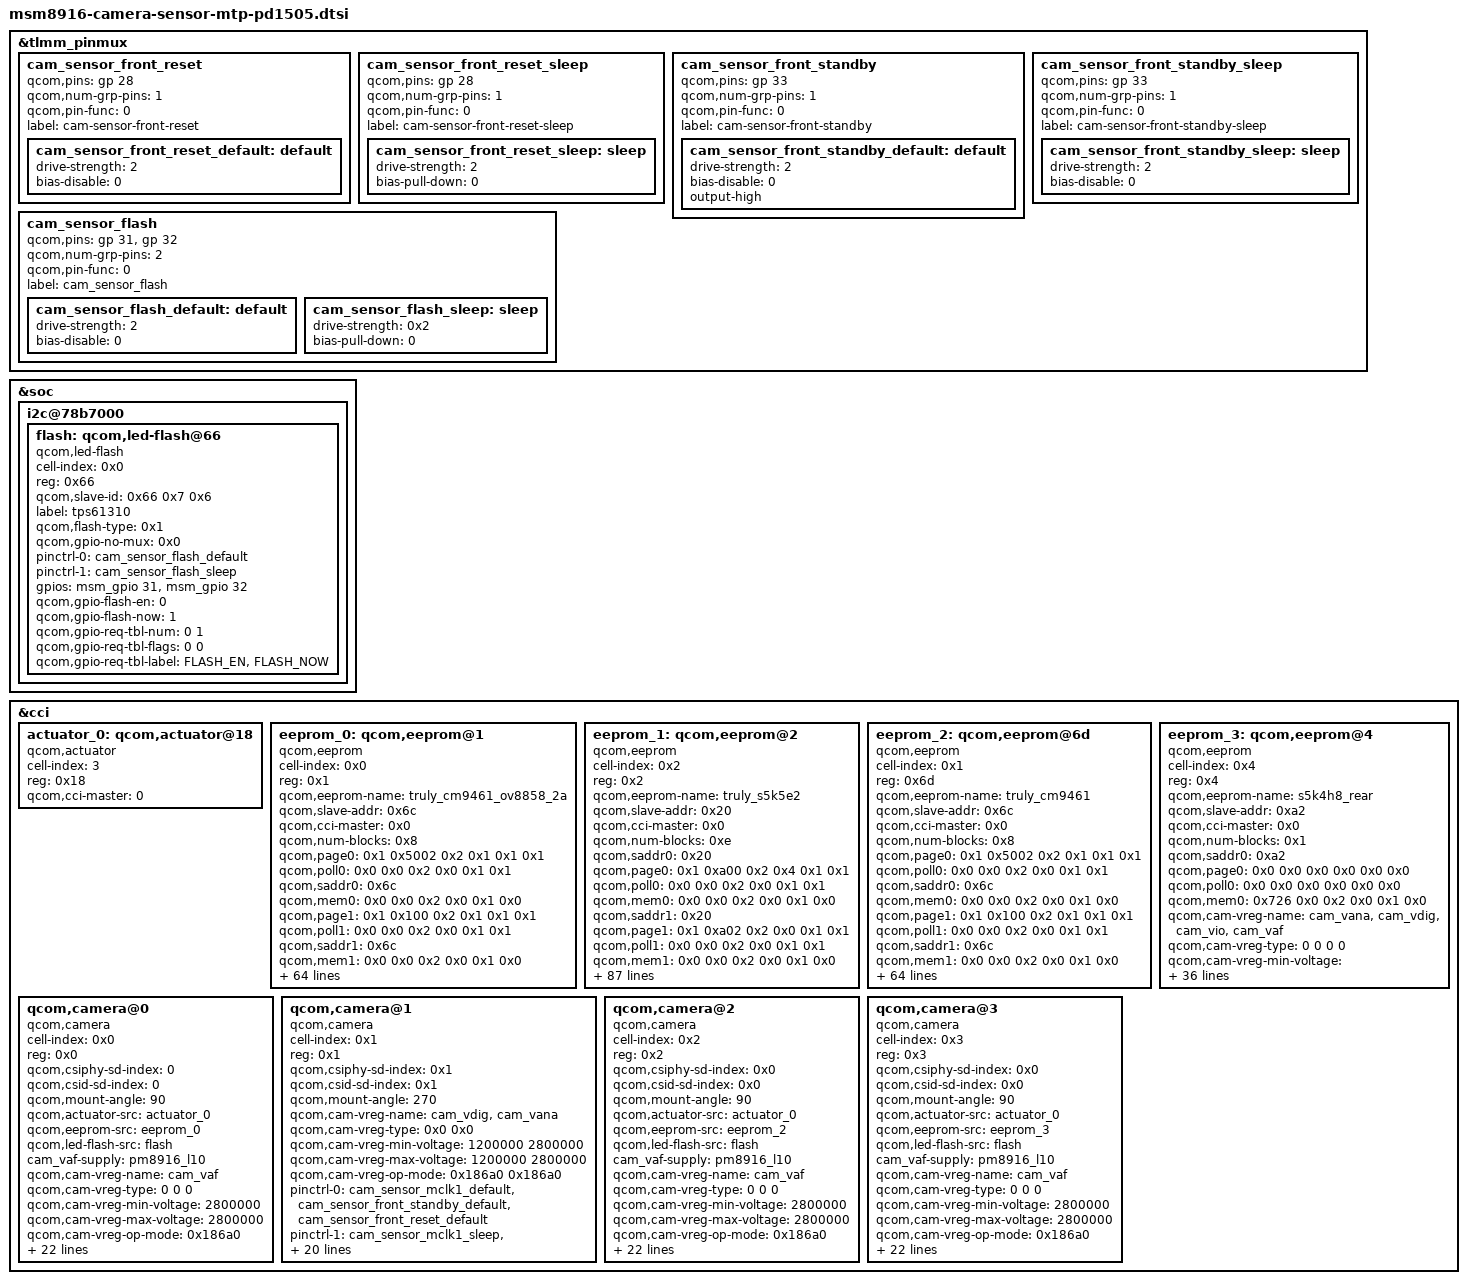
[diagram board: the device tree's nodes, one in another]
/* Copyright (c) 2020, The Linux Foundation. All rights reserved.
*  Copyright (c) 2020, the_shahnawaz_sheikh (sheikhshahnawaz41299).
*
* This program is free software; you can redistribute it and/or modify
* it under the terms of the GNU General Public License version 2 and
* only version 2 as published by the Free Software Foundation.
*
* This program is distributed in the hope that it will be useful,
* but WITHOUT ANY WARRANTY; without even the implied warranty of
* MERCHANTABILITY or FITNESS FOR A PARTICULAR PURPOSE.  See the
* GNU General Public License for more details.
*/

&tlmm_pinmux {
    
	cam_sensor_front_reset {
				qcom,pins = <&gp 28>;
				qcom,num-grp-pins = <1>;
				qcom,pin-func = <0>;
				label = "cam-sensor-front-reset";

			cam_sensor_front_reset_default:	default {
					drive-strength = <2>;
					bias-disable = <0>;
				};
			};
			
	cam_sensor_front_reset_sleep {
				qcom,pins = <&gp 28>;
				qcom,num-grp-pins = <1>;
				qcom,pin-func = <0>;
				label = "cam-sensor-front-reset-sleep";

			cam_sensor_front_reset_sleep: sleep {
					drive-strength = <2>;
					bias-pull-down = <0>;
				};
	};

	cam_sensor_front_standby {
				qcom,pins = <&gp 33>;
				qcom,num-grp-pins = <1>;
				qcom,pin-func = <0>;
				label = "cam-sensor-front-standby";

				cam_sensor_front_standby_default: default {
					drive-strength = <2>;
					bias-disable = <0>;
					output-high;
				};
	};

	cam_sensor_front_standby_sleep {
				qcom,pins = <&gp 33>;
				qcom,num-grp-pins = <1>;
				qcom,pin-func = <0>;
				label = "cam-sensor-front-standby-sleep";

			cam_sensor_front_standby_sleep:	sleep {
					drive-strength = <2>;
					bias-disable = <0>;
				};
	};
	
	cam_sensor_flash {
				qcom,pins = <&gp 31 &gp 32>;
				qcom,num-grp-pins = <2>;
				qcom,pin-func = <0>;
				label = "cam_sensor_flash";

			cam_sensor_flash_default:	default {
					drive-strength = <2>;
					bias-disable = <0>;
				};

				cam_sensor_flash_sleep: sleep {
					drive-strength = <0x2>;
					bias-pull-down = <0>;
				};
	};
};

&soc {
    
	i2c@78b7000 {
	   flash: qcom,led-flash@66 {
				cell-index = <0x0>;
				reg = <0x66>;
				qcom,slave-id = <0x66 0x7 0x6>;
				compatible = "qcom,led-flash";
				label = "tps61310";
				qcom,flash-type = <0x1>;
				qcom,gpio-no-mux = <0x0>;
				pinctrl-names = "cam_flash_default", "cam_flash_suspend";
				pinctrl-0 = <&cam_sensor_flash_default>;
				pinctrl-1 = <&cam_sensor_flash_sleep>;
				gpios = <&msm_gpio 31 0>,
				        <&msm_gpio 32 0>;
				qcom,gpio-flash-en = <0>;
				qcom,gpio-flash-now = <1>;
				qcom,gpio-req-tbl-num = <0 1>;
				qcom,gpio-req-tbl-flags = <0 0>;
				qcom,gpio-req-tbl-label = "FLASH_EN", "FLASH_NOW";
			};
	};
};

&cci {
	/delete-node/ qcom,actuator@0;
	/delete-node/ qcom,led-flash@0;

	actuator_0: qcom,actuator@18 {
		cell-index = <3>;
		reg = <0x18>;
		compatible = "qcom,actuator";
		qcom,cci-master = <0>;
	};

	/delete-node/ qcom,eeprom@20;
	/delete-node/ qcom,eeprom@1;

	eeprom_0: qcom,eeprom@1 {
				cell-index = <0x0>;
				reg = <0x1>;
				qcom,eeprom-name = "truly_cm9461_ov8858_2a";
				compatible = "qcom,eeprom";
				qcom,slave-addr = <0x6c>;
				qcom,cci-master = <0x0>;
				qcom,num-blocks = <0x8>;
				
				qcom,page0 = <0x1 0x5002 0x2 0x1 0x1 0x1>;
				qcom,poll0 = <0x0 0x0 0x2 0x0 0x1 0x1>;
				qcom,saddr0 = <0x6c>;
				qcom,mem0 = <0x0 0x0 0x2 0x0 0x1 0x0>;
				
				qcom,page1 = <0x1 0x100 0x2 0x1 0x1 0x1>;
				qcom,poll1 = <0x0 0x0 0x2 0x0 0x1 0x1>;
				qcom,saddr1 = <0x6c>;
				qcom,mem1 = <0x0 0x0 0x2 0x0 0x1 0x0>;
				
				qcom,page2 = <0x1 0x3d88 0x2 0x70 0x1 0x1>;
				qcom,poll2 = <0x0 0x0 0x2 0x0 0x1 0x1>;
				qcom,saddr2 = <0x6c>;
				qcom,mem2 = <0x0 0x0 0x2 0x0 0x1 0x0>;
				
				qcom,page3 = <0x1 0x3d89 0x2 0x10 0x1 0x1>;
				qcom,poll3 = <0x0 0x0 0x2 0x0 0x1 0x1>;
				qcom,saddr3 = <0x6c>;
				qcom,mem3 = <0x0 0x0 0x2 0x0 0x1 0x0>;
				
				qcom,page4 = <0x1 0x3d8a 0x2 0x72 0x1 0x1>;
				qcom,poll4 = <0x0 0x0 0x2 0x0 0x1 0x1>;
				qcom,saddr4 = <0x6c>;
				qcom,mem4 = <0x0 0x0 0x2 0x0 0x1 0x0>;
				
				qcom,page5 = <0x1 0x3d8b 0x2 0xa 0x1 0x1>;
				qcom,poll5 = <0x0 0x0 0x2 0x0 0x1 0x1>;
				qcom,saddr5 = <0x6c>;
				qcom,mem5 = <0x0 0x0 0x2 0x0 0x1 0x0>;
				
				qcom,page6 = <0x1 0x3d84 0x2 0xc0 0x1 0x1>;
				qcom,pageen6 = <0x1 0x3d81 0x2 0x1 0x1 0xa>;
				qcom,poll6 = <0x0 0x0 0x2 0x0 0x1 0x1>;
				qcom,saddr6 = <0x6c>;
				qcom,mem6 = <0x1fb 0x7010 0x2 0x0 0x1 0x0>;
				
				qcom,page7 = <0x1 0x5002 0x2 0x8 0x1 0x1>;
				qcom,poll7 = <0x0 0x0 0x2 0x0 0x1 0x1>;
				qcom,saddr7 = <0x6c>;
				qcom,mem7 = <0x0 0x0 0x2 0x0 0x1 0x0>;
				
				qcom,cam-vreg-name = "cam_vana", "cam_vdig", "cam_vio", "cam_vaf";
				qcom,cam-vreg-type = <0 0 0 0>;
				qcom,cam-vreg-min-voltage = <2850000 1200000 1800000 280000>;
				qcom,cam-vreg-max-voltage = <2850000 1200000 1800000 280000>;
				qcom,cam-vreg-op-mode = <0x186a0 0x186a0 0x186a0 0x186a0>;
				
				pinctrl-names = "cam_default", "cam_suspend";
				pinctrl-0 = <&cam_sensor_mclk0_default &cam_sensor_rear_default>;
				pinctrl-1 = <&cam_sensor_mclk0_sleep &cam_sensor_rear_sleep>;
				gpios = <&msm_gpio 26 0>,
				        <&msm_gpio 35 0>,
						<&msm_gpio 52 0>,
						<&msm_gpio 1 0>,
						<&msm_gpio 16 0>,
						<&msm_gpio 34 0>;
				qcom,gpio-reset = <1>;
				qcom,gpio-vana = <2>;
				qcom,gpio-vdig = <3>;
				qcom,gpio-vio = <4>;
				qcom,gpio-standby = <5>;
				qcom,gpio-req-tbl-num = <0 1 2 3 4 5>;
				qcom,gpio-req-tbl-flags = <1 0 0 0 0 0>;
				qcom,csi-lane-assign = <0x4320>;
				qcom,csi-lane-mask = <0x1f>;
				qcom,gpio-req-tbl-label = "CAMIF_MCLK",
				                     "CAM_RESET1",
									 "CAM_VANA",
									 "CAM_VDIG",
									 "CAM_VIO",
									 "CAM_STANDBY";
				qcom,cam-power-seq-type = "sensor_gpio", "sensor_gpio", "sensor_gpio",
				                       "sensor_clk", "sensor_gpio", "sensor_gpio";
				qcom,cam-power-seq-val = "sensor_gpio_vio", "sensor_gpio_vana", "sensor_gpio_vdig", 
				                    "sensor_cam_mclk", "sensor_gpio_standby", "sensor_gpio_reset";
				qcom,cam-power-seq-cfg-val = <1 1 1 23880000 1 1>;
				qcom,cam-power-seq-delay = <1 1 1 5 5 10>;
				qcom,mclk-23880000;
				clocks = <&clock_gcc clk_mclk0_clk_src>,
			            <&clock_gcc clk_gcc_camss_mclk0_clk>;
		        clock-names = "cam_src_clk", "cam_clk";
			};

	eeprom_1: qcom,eeprom@2 {
				cell-index = <0x2>;
				reg = <0x2>;
				qcom,eeprom-name = "truly_s5k5e2";
				compatible = "qcom,eeprom";
				qcom,slave-addr = <0x20>;
				qcom,cci-master = <0x0>;
				qcom,num-blocks = <0xe>;
				
				qcom,saddr0 = <0x20>;
				qcom,page0 = <0x1 0xa00 0x2 0x4 0x1 0x1>;
				qcom,poll0 = <0x0 0x0 0x2 0x0 0x1 0x1>;
				qcom,mem0 = <0x0 0x0 0x2 0x0 0x1 0x0>;
				
				qcom,saddr1 = <0x20>;
				qcom,page1 = <0x1 0xa02 0x2 0x0 0x1 0x1>;
				qcom,poll1 = <0x0 0x0 0x2 0x0 0x1 0x1>;
				qcom,mem1 = <0x0 0x0 0x2 0x0 0x1 0x0>;
				
				qcom,saddr2 = <0x20>;
				qcom,page2 = <0x1 0xa00 0x2 0x1 0x1 0x1>;
				qcom,poll2 = <0x0 0x0 0x2 0x0 0x1 0x1>;
				qcom,mem2 = <0x0 0x0 0x2 0x0 0x1 0x0>;
				
				qcom,saddr3 = <0x20>;
				qcom,page3 = <0x1 0xa02 0x2 0x2 0x1 0x1>;
				qcom,pageen3 = <0x0 0x0 0x2 0x0 0x1 0x1>;
				qcom,poll3 = <0x0 0x0 0x2 0x0 0x1 0x1>;
				qcom,mem3 = <0x40 0xa04 0x2 0x0 0x1 0x0>;
				
				qcom,saddr4 = <0x20>;
				qcom,page4 = <0x1 0xa00 0x2 0x4 0x1 0x1>;
				qcom,poll4 = <0x0 0x0 0x2 0x0 0x1 0x1>;
				qcom,mem4 = <0x0 0x0 0x2 0x0 0x1 0x0>;
				
				qcom,saddr5 = <0x20>;
				qcom,page5 = <0x1 0xa02 0x2 0x1 0x1 0x1>;
				qcom,poll5 = <0x0 0x0 0x2 0x0 0x1 0x1>;
				qcom,mem5 = <0x0 0x0 0x2 0x0 0x1 0x0>;
				
				qcom,saddr6 = <0x20>;
				qcom,page6 = <0x1 0xa00 0x2 0x1 0x1 0x1>;
				qcom,poll6 = <0x0 0x0 0x2 0x0 0x1 0x1>;
				qcom,mem6 = <0x0 0x0 0x2 0x0 0x1 0x0>;
				
				qcom,saddr7 = <0x20>;
				qcom,page7 = <0x1 0xa02 0x2 0x3 0x1 0x1>;
				qcom,pageen7 = <0x0 0x0 0x2 0x0 0x1 0x1>;
				qcom,poll7 = <0x0 0x0 0x2 0x0 0x1 0x1>;
				qcom,mem7 = <0x40 0xa04 0x2 0x0 0x1 0x0>;
				
				qcom,saddr8 = <0x20>;
				qcom,page8 = <0x1 0xa00 0x2 0x4 0x1 0x1>;
				qcom,poll8 = <0x0 0x0 0x2 0x0 0x1 0x1>;
				qcom,mem8 = <0x0 0x0 0x2 0x0 0x1 0x0>;
				
				qcom,saddr9 = <0x20>;
				qcom,page9 = <0x1 0xa02 0x2 0x2 0x1 0x1>;
				qcom,poll9 = <0x0 0x0 0x2 0x0 0x1 0x1>;
				qcom,mem9 = <0x0 0x0 0x2 0x0 0x1 0x0>;
				
				qcom,saddr10 = <0x20>;
				qcom,page10 = <0x1 0xa00 0x2 0x1 0x1 0x1>;
				qcom,poll10 = <0x0 0x0 0x2 0x0 0x1 0x1>;
				qcom,mem10 = <0x0 0x0 0x2 0x0 0x1 0x0>;
				
				qcom,saddr11 = <0x20>;
				qcom,page11 = <0x1 0xa02 0x2 0x4 0x1 0x1>;
				qcom,pageen11 = <0x0 0x0 0x2 0x0 0x1 0x1>;
				qcom,poll11 = <0x0 0x0 0x2 0x0 0x1 0x1>;
				qcom,mem11 = <0x40 0xa04 0x2 0x0 0x1 0x0>;
				
				qcom,saddr12 = <0x20>;
				qcom,page12 = <0x1 0xa00 0x2 0x4 0x1 0x1>;
				qcom,poll12 = <0x0 0x0 0x2 0x0 0x1 0x1>;
				qcom,mem12 = <0x0 0x0 0x2 0x0 0x1 0x0>;
				
				qcom,saddr13 = <0x20>;
				qcom,page13 = <0x1 0xa00 0x2 0x0 0x1 0x1>;
				qcom,poll13 = <0x0 0x0 0x2 0x0 0x1 0x1>;
				qcom,mem13 = <0x0 0x0 0x2 0x0 0x1 0x0>;
				
				qcom,cam-vreg-name = "cam_vdig", "cam_vana";
				qcom,cam-vreg-type = <0 0>;
				qcom,cam-vreg-min-voltage = <1200000 2800000>;
				qcom,cam-vreg-max-voltage = <1200000 2800000>;
				qcom,cam-vreg-op-mode = <0x186a0 0x186a0>;
				qcom,gpio-no-mux = <0>;
				pinctrl-names = "cam_default", "cam_suspend";
				pinctrl-0 = <&cam_sensor_mclk1_default &cam_sensor_front_default>;
				pinctrl-1 = <&cam_sensor_mclk1_sleep &cam_sensor_front_sleep>;
				gpios = <&msm_gpio 27 0>,
				        <&msm_gpio 28 0>,
						<&msm_gpio 33 0>,
						<&msm_gpio 52 0>,
						<&msm_gpio 1 0>,
						<&msm_gpio 16 0>;
				qcom,gpio-reset = <1>;
				qcom,gpio-standby = <2>;
				qcom,gpio-vana = <3>;
				qcom,gpio-vdig = <4>;
				qcom,gpio-vio = <5>;
				qcom,gpio-req-tbl-num = <0 1 2 3 4 5>;
				qcom,gpio-req-tbl-flags = <1 0 0 0 0 0>;
				qcom,csi-lane-assign = <0x4320>;
				qcom,csi-lane-mask = <0x7>;
				qcom,gpio-req-tbl-label = "CAMIF_MCLK", "CAM_RESET", "CAM_STANDBY",
				                       "CAM_VANA1", "CAM_VDIG1", "CAM_VIO";
				qcom,cam-power-seq-type = "sensor_gpio", "sensor_gpio", "sensor_gpio",
				                        "sensor_clk", "sensor_gpio", "sensor_gpio";
				qcom,cam-power-seq-val = "sensor_gpio_vio", "sensor_gpio_vdig", "sensor_gpio_vana",
				                       "sensor_cam_mclk", "sensor_gpio_reset", "sensor_gpio_standby";
				qcom,cam-power-seq-cfg-val = <1 1 1 23880000 1 1>;
				qcom,cam-power-seq-delay = <5 5 5 5 10 10>;
				qcom,mclk-23880000;
				clocks = <&clock_gcc clk_mclk0_clk_src>,
			            <&clock_gcc clk_gcc_camss_mclk0_clk>;
		        clock-names = "cam_src_clk", "cam_clk";
			};

	eeprom_2: qcom,eeprom@6d {
				cell-index = <0x1>;
				reg = <0x6d>;
				qcom,eeprom-name = "truly_cm9461";
				compatible = "qcom,eeprom";
				qcom,slave-addr = <0x6c>;
				qcom,cci-master = <0x0>;
				qcom,num-blocks = <0x8>;
				qcom,page0 = <0x1 0x5002 0x2 0x1 0x1 0x1>;
				qcom,poll0 = <0x0 0x0 0x2 0x0 0x1 0x1>;
				
				qcom,saddr0 = <0x6c>;
				qcom,mem0 = <0x0 0x0 0x2 0x0 0x1 0x0>;
				
				qcom,page1 = <0x1 0x100 0x2 0x1 0x1 0x1>;
				qcom,poll1 = <0x0 0x0 0x2 0x0 0x1 0x1>;
				qcom,saddr1 = <0x6c>;
				qcom,mem1 = <0x0 0x0 0x2 0x0 0x1 0x0>;
				
				qcom,page2 = <0x1 0x3d88 0x2 0x70 0x1 0x1>;
				qcom,poll2 = <0x0 0x0 0x2 0x0 0x1 0x1>;
				qcom,saddr2 = <0x6c>;
				qcom,mem2 = <0x0 0x0 0x2 0x0 0x1 0x0>;
				
				qcom,page3 = <0x1 0x3d89 0x2 0x10 0x1 0x1>;
				qcom,poll3 = <0x0 0x0 0x2 0x0 0x1 0x1>;
				qcom,saddr3 = <0x6c>;
				qcom,mem3 = <0x0 0x0 0x2 0x0 0x1 0x0>;
				
				qcom,page4 = <0x1 0x3d8a 0x2 0x72 0x1 0x1>;
				qcom,poll4 = <0x0 0x0 0x2 0x0 0x1 0x1>;
				qcom,saddr4 = <0x6c>;
				qcom,mem4 = <0x0 0x0 0x2 0x0 0x1 0x0>;
				
				qcom,page5 = <0x1 0x3d8b 0x2 0xa 0x1 0x1>;
				qcom,poll5 = <0x0 0x0 0x2 0x0 0x1 0x1>;
				qcom,saddr5 = <0x6c>;
				qcom,mem5 = <0x0 0x0 0x2 0x0 0x1 0x0>;
				
				qcom,page6 = <0x1 0x3d84 0x2 0xc0 0x1 0x1>;
				qcom,pageen6 = <0x1 0x3d81 0x2 0x1 0x1 0xa>;
				qcom,poll6 = <0x0 0x0 0x2 0x0 0x1 0x1>;
				qcom,saddr6 = <0x6c>;
				qcom,mem6 = <0x1fb 0x7010 0x2 0x0 0x1 0x0>;
				
				qcom,page7 = <0x1 0x5002 0x2 0x8 0x1 0x1>;
				qcom,poll7 = <0x0 0x0 0x2 0x0 0x1 0x1>;
				qcom,saddr7 = <0x6c>;
				qcom,mem7 = <0x0 0x0 0x2 0x0 0x1 0x0>;
				
				qcom,cam-vreg-name = "cam_vana", "cam_vdig", "cam_vio", "cam_vaf";
				qcom,cam-vreg-type = <0x0 0x0 0x0 0x0>;
				qcom,cam-vreg-min-voltage = <2850000 1200000 1800000 280000>;
				qcom,cam-vreg-max-voltage = <2850000 1200000 1800000 280000>;
				qcom,cam-vreg-op-mode = <0x186a0 0x186a0 0x186a0 0x186a0>;
				pinctrl-names = "cam_default", "cam_suspend";
				pinctrl-0 = <&cam_sensor_mclk0_default &cam_sensor_rear_default>;
				pinctrl-1 = <&cam_sensor_mclk0_sleep &cam_sensor_rear_sleep>;
				gpios = <&msm_gpio 26 0>,
				         <&msm_gpio 35 0>,
						 <&msm_gpio 52 0>,
						 <&msm_gpio 1 0>,
						 <&msm_gpio 16 0>,
						 <&msm_gpio 34 0>;
				qcom,gpio-reset = <1>;
				qcom,gpio-vana = <2>;
				qcom,gpio-vdig = <3>;
				qcom,gpio-vio = <4>;
				qcom,gpio-standby = <5>;
				qcom,gpio-req-tbl-num = <0 1 2 3 4 5>;
				qcom,gpio-req-tbl-flags = <1 0 0 0 0 0>;
				qcom,csi-lane-assign = <0x4320>;
				qcom,csi-lane-mask = <0x1f>;
				qcom,gpio-req-tbl-label = "CAMIF_MCLK", "CAM_RESET1", "CAM_VANA", 
				                       "CAM_VDIG", "CAM_VIO", "CAM_STANDBY";
				qcom,cam-power-seq-type = "sensor_gpio", "sensor_gpio", "sensor_gpio",
				                         "sensor_clk", "sensor_gpio", "sensor_gpio";
				qcom,cam-power-seq-val = "sensor_gpio_vio", "sensor_gpio_vana", "sensor_gpio_vdig",
				                       "sensor_cam_mclk", "sensor_gpio_standby", "sensor_gpio_reset";
				qcom,cam-power-seq-cfg-val = <1 1 1 23880000 1 1>;
				qcom,cam-power-seq-delay = <1 1 1 5 5 10>;
				qcom,mclk-23880000;
				clocks = <&clock_gcc clk_mclk0_clk_src>,
			            <&clock_gcc clk_gcc_camss_mclk0_clk>;
		        clock-names = "cam_src_clk", "cam_clk";
			};

	eeprom_3: qcom,eeprom@4 {
				cell-index = <0x4>;
				reg = <0x4>;
				qcom,eeprom-name = "s5k4h8_rear";
				compatible = "qcom,eeprom";
				qcom,slave-addr = <0xa2>;
				qcom,cci-master = <0x0>;
				qcom,num-blocks = <0x1>;
				
				qcom,saddr0 = <0xa2>;
				qcom,page0 = <0x0 0x0 0x0 0x0 0x0 0x0>;
				qcom,poll0 = <0x0 0x0 0x0 0x0 0x0 0x0>;
				qcom,mem0 = <0x726 0x0 0x2 0x0 0x1 0x0>;
				
				qcom,cam-vreg-name = "cam_vana", "cam_vdig", "cam_vio", "cam_vaf";
				qcom,cam-vreg-type = <0 0 0 0>;
				qcom,cam-vreg-min-voltage = <2850000 1200000 1800000 280000>;
				qcom,cam-vreg-max-voltage = <2850000 1200000 1800000 280000>;
				qcom,cam-vreg-op-mode = <0x186a0 0x186a0 0x186a0 0x186a0>;
				
				pinctrl-names = "cam_default", "cam_suspend";
				pinctrl-0 = <&cam_sensor_mclk0_default &cam_sensor_rear_default>;
				pinctrl-1 = <&cam_sensor_mclk0_sleep &cam_sensor_rear_sleep>;
				gpios = <&msm_gpio 26 0>,
				        <&msm_gpio 35 0>,
						<&msm_gpio 52 0>,
						<&msm_gpio 1 0>,
						<&msm_gpio 16 0>,
						<&msm_gpio 34 0>;
				qcom,gpio-reset = <1>;
				qcom,gpio-vana = <2>;
				qcom,gpio-vdig = <3>;
				qcom,gpio-vio = <4>;
				qcom,gpio-standby = <5>;
				qcom,gpio-req-tbl-num = <0 1 2 3 4 5>;
				qcom,gpio-req-tbl-flags = <1 0 0 0 0 0>;
				qcom,csi-lane-assign = <0x4320>;
				qcom,csi-lane-mask = <0x1f>;
				qcom,gpio-req-tbl-label = "CAMIF_MCLK", "CAM_RESET1", "CAM_VANA",
				                         "CAM_VDIG", "CAM_VIO", "CAM_STANDBY";
				qcom,cam-power-seq-type = "sensor_gpio", "sensor_gpio", "sensor_gpio",
				                          "sensor_clk", "sensor_gpio", "sensor_gpio";
				qcom,cam-power-seq-val = "sensor_gpio_vio", "sensor_gpio_vana", "sensor_gpio_vdig", 
				                        "sensor_cam_mclk", "sensor_gpio_standby", "sensor_gpio_reset";
				qcom,cam-power-seq-cfg-val = <1 1 1 238800000 1 1>;
				qcom,cam-power-seq-delay = <1 1 1 5 5 10>;
				qcom,mclk-23880000;
				clocks = <&clock_gcc clk_mclk0_clk_src>,
			            <&clock_gcc clk_gcc_camss_mclk0_clk>;
		        clock-names = "cam_src_clk", "cam_clk";
			};

	/delete-node/ qcom,camera@78;
	/delete-node/ qcom,camera@0;
	/delete-node/ qcom,camera@1;

	qcom,camera@0 {
				cell-index = <0x0>;
				compatible = "qcom,camera";
				reg = <0x0>;
				qcom,csiphy-sd-index = <0>;
				qcom,csid-sd-index = <0>;
				qcom,mount-angle = <90>;
				qcom,actuator-src = <&actuator_0>;
				qcom,eeprom-src = <&eeprom_0>;
				qcom,led-flash-src = <&flash>;
				cam_vaf-supply = <&pm8916_l10>;
				qcom,cam-vreg-name = "cam_vaf";
				qcom,cam-vreg-type = <0 0 0>;
				qcom,cam-vreg-min-voltage = <2800000>;
				qcom,cam-vreg-max-voltage = <2800000>;
				qcom,cam-vreg-op-mode = <0x186a0>;
				pinctrl-names = "cam_default", "cam_suspend";
				pinctrl-0 = <&cam_sensor_mclk0_default &cam_sensor_rear_default>;
				pinctrl-1 = <&cam_sensor_mclk0_sleep &cam_sensor_rear_sleep>;
				gpios = <&msm_gpio 26 0>,
				        <&msm_gpio 35 0>,
						<&msm_gpio 34 0>,
						<&msm_gpio 52 0>,
						<&msm_gpio 1 0>,
						<&msm_gpio 16 0>;
				qcom,gpio-reset = <1>;
				qcom,gpio-standby = <2>;
				qcom,gpio-vana = <3>;
				qcom,gpio-vdig = <4>;
				qcom,gpio-vio = <5>;
				qcom,gpio-req-tbl-num = <0 1 2 3 4 5>;
				qcom,gpio-req-tbl-flags = <1 0 0 0 0 0>;
				qcom,gpio-req-tbl-label = "CAMIF_MCLK", "CAM_RESET1", "CAM_STANDBY", "CAM_VANA", "CAM_VDIG", "CAM_VIO";
				qcom,sensor-position = <0x0>;
				qcom,sensor-mode = <0x0>;
				qcom,cci-master = <0x0>;
				qcom,mclk-23880000;
				status = "ok";
				clocks = <&clock_gcc clk_mclk0_clk_src>,
			            <&clock_gcc clk_gcc_camss_mclk0_clk>;
		        clock-names = "cam_src_clk", "cam_clk";
			};

	qcom,camera@1 {
				cell-index = <0x1>;
				compatible = "qcom,camera";
				reg = <0x1>;
				qcom,csiphy-sd-index = <0x1>;
				qcom,csid-sd-index = <0x1>;
				qcom,mount-angle = <270>;
				qcom,cam-vreg-name = "cam_vdig", "cam_vana";
				qcom,cam-vreg-type = <0x0 0x0>;
				qcom,cam-vreg-min-voltage = <1200000 2800000>;
				qcom,cam-vreg-max-voltage = <1200000 2800000>;
				qcom,cam-vreg-op-mode = <0x186a0 0x186a0>;
				pinctrl-names = "cam_default", "cam_suspend";
				pinctrl-0 = <&cam_sensor_mclk1_default &cam_sensor_front_standby_default &cam_sensor_front_reset_default>;
				pinctrl-1 = <&cam_sensor_mclk1_sleep &cam_sensor_front_standby_sleep &cam_sensor_front_reset_sleep>;
				gpios = <&msm_gpio 27 0>,
				        <&msm_gpio 28 0>,
						<&msm_gpio 33 0>,
						<&msm_gpio 52 0>,
						<&msm_gpio 16 0>,
						<&msm_gpio 16 0>;
				qcom,gpio-reset = <1>;
				qcom,gpio-standby = <2>;
				qcom,gpio-vana = <3>;
				qcom,gpio-vdig = <4>;
				qcom,gpio-vio = <5>;
				qcom,gpio-req-tbl-num = <0 1 2 3 4 5>;
				qcom,gpio-req-tbl-flags = <1 0 0 0 0 0>;
				qcom,gpio-req-tbl-label = "CAMIF_MCLK", "CAM_RESET", "CAM_STANDBY", "CAM_VANA1", "CAM_VDIG1", "CAM_VIO";
				qcom,sensor-position = <1>;
				qcom,sensor-mode = <0x0>;
				qcom,cci-master = <0x0>;
				qcom,mclk-23880000;
				status = "ok";
				clocks = <&clock_gcc clk_mclk0_clk_src>,
			            <&clock_gcc clk_gcc_camss_mclk0_clk>;
		        clock-names = "cam_src_clk", "cam_clk";
			};

	qcom,camera@2 {
				cell-index = <0x2>;
				compatible = "qcom,camera";
				reg = <0x2>;
				qcom,csiphy-sd-index = <0x0>;
				qcom,csid-sd-index = <0x0>;
				qcom,mount-angle = <90>;
				qcom,actuator-src = <&actuator_0>;
				qcom,eeprom-src = <&eeprom_2>;
				qcom,led-flash-src = <&flash>;
				cam_vaf-supply = <&pm8916_l10>;
				qcom,cam-vreg-name = "cam_vaf";
				qcom,cam-vreg-type = <0 0 0>;
				qcom,cam-vreg-min-voltage = <2800000>;
				qcom,cam-vreg-max-voltage = <2800000>;
				qcom,cam-vreg-op-mode = <0x186a0>;
				pinctrl-names = "cam_default", "cam_suspend";
				pinctrl-0 = <&cam_sensor_mclk0_default &cam_sensor_rear_default>;
				pinctrl-1 = <&cam_sensor_mclk0_sleep &cam_sensor_rear_sleep>;
				gpios = <&msm_gpio 26 0>,
				        <&msm_gpio 35 0>,
						<&msm_gpio 34 0>,
						<&msm_gpio 52 0>,
						<&msm_gpio 1 0>,
						<&msm_gpio 16 0>;
				qcom,gpio-reset = <1>;
				qcom,gpio-standby = <2>;
				qcom,gpio-vana = <3>;
				qcom,gpio-vdig = <4>;
				qcom,gpio-vio = <5>;
				qcom,gpio-req-tbl-num = <0 1 2 3 4 5>;
				qcom,gpio-req-tbl-flags = <1 0 0 0 0 0>;
				qcom,gpio-req-tbl-label = "CAMIF_MCLK", "CAM_RESET1", "CAM_STANDBY", "CAM_VANA", "CAM_VDIG", "CAM_VIO";
				qcom,sensor-position = <0x0>;
				qcom,sensor-mode = <0x0>;
				qcom,cci-master = <0x0>;
				qcom,mclk-23880000;
				status = "ok";
				clocks = <&clock_gcc clk_mclk0_clk_src>,
			            <&clock_gcc clk_gcc_camss_mclk0_clk>;
		        clock-names = "cam_src_clk", "cam_clk";
	};

	qcom,camera@3 {
				cell-index = <0x3>;
				compatible = "qcom,camera";
				reg = <0x3>;
				qcom,csiphy-sd-index = <0x0>;
				qcom,csid-sd-index = <0x0>;
				qcom,mount-angle = <90>;
				qcom,actuator-src = <&actuator_0>;
				qcom,eeprom-src = <&eeprom_3>;
				qcom,led-flash-src = <&flash>;
				cam_vaf-supply = <&pm8916_l10>;
				qcom,cam-vreg-name = "cam_vaf";
				qcom,cam-vreg-type = <0 0 0>;
				qcom,cam-vreg-min-voltage = <2800000>;
				qcom,cam-vreg-max-voltage = <2800000>;
				qcom,cam-vreg-op-mode = <0x186a0>;
				pinctrl-names = "cam_default", "cam_suspend";
				pinctrl-0 = <&cam_sensor_mclk0_default &cam_sensor_rear_default>;
				pinctrl-1 = <&cam_sensor_mclk0_sleep &cam_sensor_rear_sleep>;
				gpios = <&msm_gpio 26 0>,
				         <&msm_gpio 35 0>,
						 <&msm_gpio 34 0>,
						 <&msm_gpio 52 0>,
						 <&msm_gpio 1 0>,
						 <&msm_gpio 16 0>;
				qcom,gpio-reset = <1>;
				qcom,gpio-standby = <2>;
				qcom,gpio-vana = <3>;
				qcom,gpio-vdig = <4>;
				qcom,gpio-vio = <5>;
				qcom,gpio-req-tbl-num = <0 1 2 3 4 5>;
				qcom,gpio-req-tbl-flags = <1 0 0 0 0 0>;
				qcom,gpio-req-tbl-label = "CAMIF_MCLK", "CAM_RESET1", "CAM_STANDBY", "CAM_VANA", "CAM_VDIG", "CAM_VIO";
				qcom,sensor-position = <0x0>;
				qcom,sensor-mode = <0x0>;
				qcom,cci-master = <0x0>;
				qcom,mclk-23880000;
				status = "ok";
				clocks = <&clock_gcc clk_mclk0_clk_src>,
			            <&clock_gcc clk_gcc_camss_mclk0_clk>;
		        clock-names = "cam_src_clk", "cam_clk";
	};
};
